# STM32U5G9xx register map
File version: 1.0
Registers are 32-bit, read-write, reset 0x0 unless marked. A register's access mark holds for its fields unless they carry their own. Offsets are from the block's base; [hi:lo] are bit positions; {n}, {i} and the like mark numbered series.

## FDCAN_CONFIG — FD Controller Area Network Configuration
Base 0x4000A500
Same registers: FDCAN_CONFIG_S 0x5000A500
0x00 CKDIV — FDCAN clock divider register
  [3:0] PDIV — Input Clock Divider
0x204 OPTR — FDCAN option register
0x2F0 HWCFG — FDCAN hardware configuration register
0x2F4 VERR — FDCAN IP version register
0x2F8 IPIDR — FDCAN IP ID register
0x2FC SIDR — FDCAN size ID register

## GFXTIM
Base 0x40016400
Same registers: GFXTIM_S 0x50016400
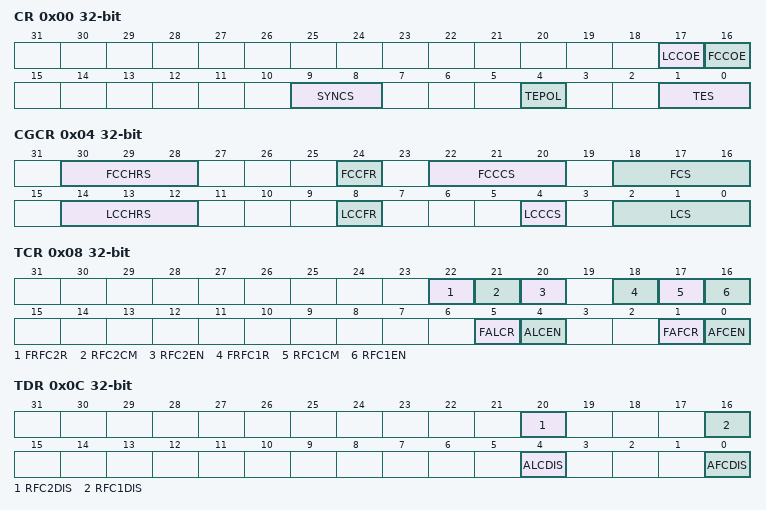
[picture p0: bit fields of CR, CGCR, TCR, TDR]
0x00 CR — GFXTIM configuration register
  [17] LCCOE, [16] FCCOE, [9:8] SYNCS, [4] TEPOL, [1:0] TES
0x04 CGCR — GFXTIM clock generator configuration register
  [30:28] FCCHRS, [24] FCCFR, [22:20] FCCCS, [18:16] FCS, [14:12] LCCHRS, [8] LCCFR, [4] LCCCS, [2:0] LCS
0x08 TCR — GFXTIM timers configuration register
  [22] FRFC2R, [21] RFC2CM, [20] RFC2EN, [18] FRFC1R, [17] RFC1CM, [16] RFC1EN, [5] FALCR, [4] ALCEN, [1] FAFCR, [0] AFCEN
0x0C TDR — GFXTIM timers disable register
  [20] RFC2DIS, [16] RFC1DIS, [4] ALCDIS, [0] AFCDIS
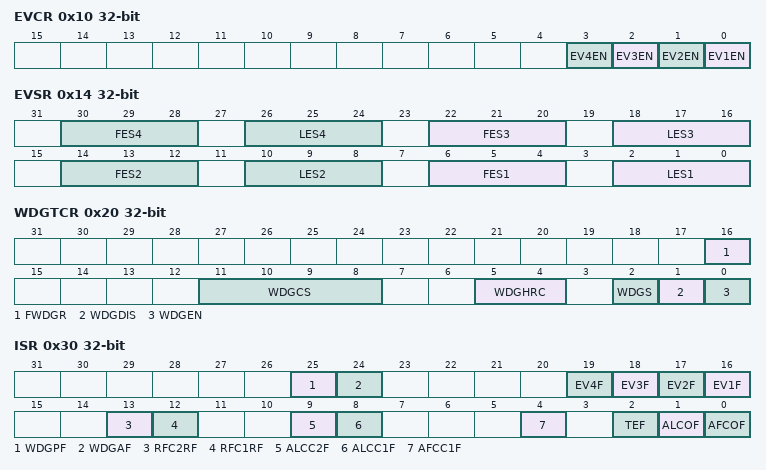
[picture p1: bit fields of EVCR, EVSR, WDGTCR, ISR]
0x10 EVCR — GFXTIM events control register
  [n-1] EV{n}EN (n=1..4)
0x14 EVSR — GFXTIM events selection register
  [8n-2:8n-4] FES{n} (n=1..4), [8n-6:8n-8] LES{n} (n=1..4)
0x20 WDGTCR — GFXTIM watchdog timer configuration register
  [16] FWDGR, [11:8] WDGCS, [5:4] WDGHRC, [2] WDGS, [1] WDGDIS, [0] WDGEN
0x30 ISR — GFXTIM interrupt status register
  [25] WDGPF, [24] WDGAF, [n+15] EV{n}F (n=1..4), [13] RFC2RF, [12] RFC1RF, [9] ALCC2F, [8] ALCC1F, [4] AFCC1F, [2] TEF, [1] ALCOF, [0] AFCOF
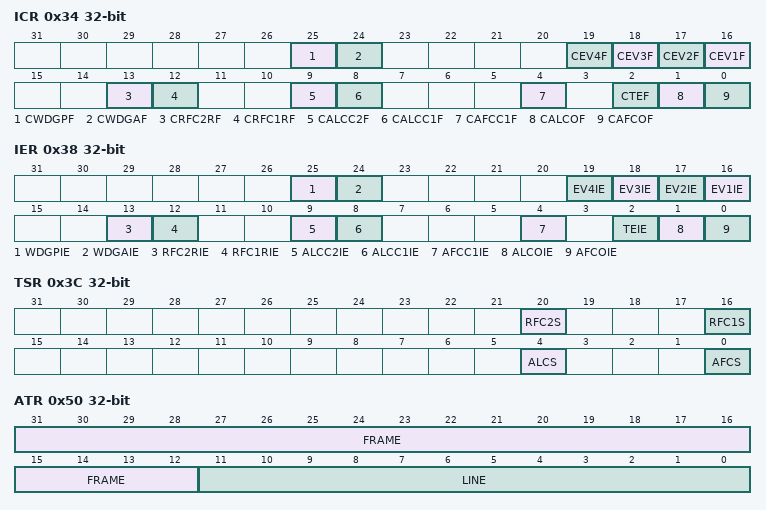
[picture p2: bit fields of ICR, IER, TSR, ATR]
0x34 ICR — GFXTIM interrupt clear register
  [25] CWDGPF, [24] CWDGAF, [n+15] CEV{n}F (n=1..4), [13] CRFC2RF, [12] CRFC1RF, [9] CALCC2F, [8] CALCC1F, [4] CAFCC1F, [2] CTEF, [1] CALCOF, [0] CAFCOF
0x38 IER — GFXTIM interrupt enable register
  [25] WDGPIE, [24] WDGAIE, [n+15] EV{n}IE (n=1..4), [13] RFC2RIE, [12] RFC1RIE, [9] ALCC2IE, [8] ALCC1IE, [4] AFCC1IE, [2] TEIE, [1] ALCOIE, [0] AFCOIE
0x3C TSR — GFXTIM timers status register
  [20] RFC2S, [16] RFC1S, [4] ALCS, [0] AFCS
0x40 LCCRR — GFXTIM line clock counter reload register
  [21:0] RELOAD
0x44 FCCRR — GFXTIM frame clock counter reload register
  [11:0] RELOAD
0x50 ATR — GFXTIM absolute time register
  [31:12] FRAME, [11:0] LINE
0x54 AFCR — GFXTIM absolute frame counter register
  [19:0] FRAME
0x58 ALCR — GFXTIM absolute line counter register
  [11:0] LINE
0x60 AFCC1R — GFXTIM absolute frame counter compare 1 register
  [19:0] FRAME
0x70 ALCC1R — GFXTIM absolute line counter compare 1 register
  [11:0] LINE
0x74 ALCC2R — GFXTIM absolute line counter compare 2 register
  [11:0] LINE
0x80 RFC1R — GFXTIM relative frame counter 1 register
  [11:0] FRAME
0x84 RFC1RR — GFXTIM relative frame counter 1 reload register
  [11:0] FRAME
0x88 RFC2R — GFXTIM relative frame counter 2 register
  [11:0] FRAME
0x8C RFC2RR — GFXTIM relative frame counter 2 reload register
  [11:0] FRAME
0xA0 WDGCR — GFXTIM watchdog counter register
  [15:0] VALUE
0xA4 WDGRR — GFXTIM watchdog reload register
  [15:0] RELOAD
0xA8 WDGPAR — GFXTIM watchdog pre-alarm register
  [15:0] PREALARM
0x3F0 HWCFGR — GFXTIM HW configuration register
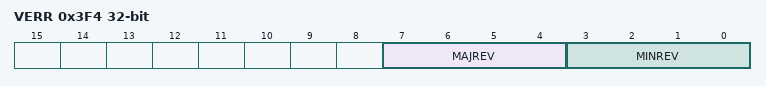
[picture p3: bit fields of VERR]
0x3F4 VERR — GFXTIM version register
  [7:4] MAJREV, [3:0] MINREV
0x3F8 IPIDR — GFXTIM identification register
  [31:0] ID
0x3FC SIDR — GFXTIM size identification register
  [31:0] SID

## CORDIC
Base 0x40021000
Same registers: CORDIC_S 0x50021000
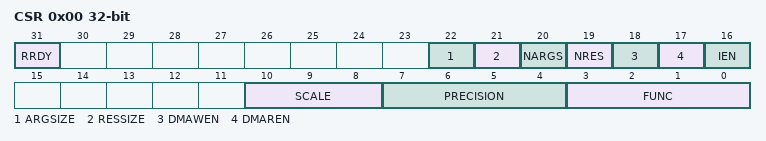
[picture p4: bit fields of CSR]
0x00 CSR — CORDIC control and status register
  [31] RRDY — Result Ready Flag
  [22] ARGSIZE — Width of input data
    0=INSIZE_32BITS (32 bits input data size (Q1.31 format)); 1=INSIZE_16BITS (16 bits input data size (Q1.15 format))
  [21] RESSIZE — Width of output data
    0=OUTSIZE_32BITS (32 bits output data size (Q1.31 format)); 1=OUTSIZE_16BITS (16 bits output data size (Q1.15 format))
  [20] NARGS — Number of arguments in RDATA register
    0=NBWRITE_1; 1=NBWRITE_2
  [19] NRES — Number of results in WDATA register
    0=NBREAD_1; 1=NBREAD_2
  [18] DMAWEN — DMA Write channel Enable
  [17] DMAREN — DMA Read channel Enable
  [16] IEN — Interrupt Enable
  [10:8] SCALE — Scaling factor
  [7:4] PRECISION
    1=PRECISION_1CYCLE; {v}=PRECISION_{v}CYCLES (v=2..15)
  [3:0] FUNC — Function
    0=COSINE; 1=SINE; 2=PHASE; 3=MODULUS; 4=ARCTANGENT; 5=HCOSINE (Hyperbolic Cosine); 6=HSINE (Hyperbolic Sine); 7=HARCTANGENT (Hyperbolic Arctangent); 8=NATURALLOG (Natural Logarithm); 9=SQUAREROOT
0x04 WDATA — CORDIC argument register
  [31:0] ARG — Input Argument
0x08 RDATA — CORDIC result register
  [31:0] RES — Output Result
